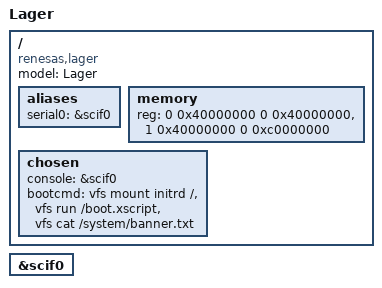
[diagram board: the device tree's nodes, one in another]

/dts-v1/;

#include "./r8a7790.dtsi"

/ {
	model = "Lager";
	compatible = "renesas,lager", "renesas,r8a7790";

	aliases {
		serial0 = &scif0;
	};

	memory {
		device_type = "memory";
		reg = <0 0x40000000 0 0x40000000>,
		      <1 0x40000000 0 0xc0000000>;
	};

	chosen {
		console = &scif0;
		bootcmd = /* Mount initrd device */
			  "vfs mount initrd /",

			  /* Run boot script */
			  "vfs run /boot.xscript",

			  /* Print banner */
			  "vfs cat /system/banner.txt";
	};
};

&scif0 {
	status = "okay";
};
